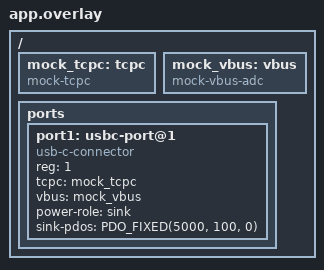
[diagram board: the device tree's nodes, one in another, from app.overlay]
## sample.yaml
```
sample:
  name: USB-C SINK
tests:
  sample.usbc.sink:
    depends_on: tcpc
    tags: usbc
    platform_allow: b_g474e_dpow1
    integration_platforms:
      - b_g474e_dpow1
    harness: console
    harness_config:
      type: one_line
      regex:
        - "Unattached.SNK"
  sample.usbc.sink.chunking:
    depends_on: tcpc
    tags: usbc
    platform_allow: b_g474e_dpow1
    integration_platforms:
      - b_g474e_dpow1
    harness: console
    harness_config:
      type: one_line
      regex:
        - "Unattached.SNK"
    extra_configs:
      - CONFIG_USBC_PRL_CHUNKING=y
```

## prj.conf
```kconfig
CONFIG_ZTEST=y
CONFIG_ZTEST_NEW_API=y

CONFIG_LOG=y
CONFIG_USB_DEVICE_LOG_LEVEL_DBG=y
CONFIG_USB_DRIVER_LOG_LEVEL_DBG=y

CONFIG_ADC=y
CONFIG_USBC_STACK=y
CONFIG_USBC_THREAD_PRIORITY=10
```

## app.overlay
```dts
/*
 * Copyright (c) 2022 The Chromium OS Authors.
 *
 * SPDX-License-Identifier: Apache-2.0
 *
 */

#include <dt-bindings/usb-c/pd.h>

/ {
	mock_tcpc: tcpc {
		compatible = "mock-tcpc";
	};

	mock_vbus: vbus {
		compatible = "mock-vbus-adc";
	};

	ports {
		#address-cells = <1>;
		#size-cells = <0>;

		port1: usbc-port@1 {
			compatible = "usb-c-connector"; 
			reg = <1>;
			tcpc = <&mock_tcpc>;
			vbus = <&mock_vbus>;
			power-role = "sink";
			sink-pdos = <PDO_FIXED(5000, 100, 0)>;
		};
	};
};
```

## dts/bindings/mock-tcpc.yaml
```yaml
# Copyright 2022 The Chromium OS Authors
# SPDX-License-Identifier: Apache-2.0

description: |
    Mock TypeC Port Controller used for testing

compatible: "mock-tcpc"

properties:
    hasvconn:
      type: boolean
      required: false
      description: xxx
```

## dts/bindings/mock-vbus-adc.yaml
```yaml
# Copyright 2022 The Chromium OS Authors
# SPDX-License-Identifier: Apache-2.0

description: |
    Mock VBUS used for testing

compatible: "mock-vbus-adc"

properties:
    hasvconn:
      type: boolean
      required: false
      description: xxx
```

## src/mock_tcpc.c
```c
/*
 * Copyright 2022 The Chromium OS Authors
 *
 * SPDX-License-Identifier: Apache-2.0
 */

#define DT_DRV_COMPAT mock_tcpc

#include <zephyr/logging/log.h>

#include <zephyr/device.h>
#include <zephyr/sys/util.h>
#include <zephyr/kernel.h>
#include <string.h>
#include <stddef.h>

#include "mock_tcpc.h"
#include "mock_tester.h"

enum tcpc_state_t test_state;

/**
 * @brief Get the state of the CC1 and CC2 lines
 *
 * @retval 0 on success
 * @retval -EIO on failure
 */
static int mt_get_cc(const struct device *dev,
		       enum tc_cc_voltage_state *cc1,
		       enum tc_cc_voltage_state *cc2)
{
	*cc1 = tester_get_cc1();
	*cc2 = tester_get_cc2();

	return 0;
}

/**
 * @brief Get the CC enable mask. The mask indicates which CC line
 *        is enabled.
 *
 * @retval CC Enable mask (bit 0: CC1, bit 1: CC2)
 */

/**
 * @brief Enable or Disable VCONN
 *
 * @retval 0 on success
 * @retval -EIO on failure
 * @retval -ENOTSUP if not supported
 */
static int mt_set_vconn(const struct device *dev, bool enable)
{
//	const struct mock_tcpc_config *const config = dev->config;
//	struct mock_tcpc_data *data = dev->data;

	return 0; //ret;
}

/**
 * @brief Sets the value of the CC pull up resistor used when operating as a Source
 *
 * @retval 0 on success
 */
static int mt_select_rp_value(const struct device *dev, enum tc_rp_value rp)
{
//	const struct mock_tcpc_config *const config = dev->config;
//	struct mock_tcpc_data *data = dev->data;

//	data->rp = rp;

	return 0;
}

/**
 * @brief Gets the value of the CC pull up resistor used when operating as a Source
 *
 * @retval 0 on success
 */
static int mt_get_rp_value(const struct device *dev, enum tc_rp_value *rp)
{
//	struct tcpc_data *data = dev->data;

//	*rp = data->rp;

	return 0;
}

/**
 * @brief Set the CC pull up or pull down resistors
 *
 * @retval 0 on success
 * @retval -EIO on failure
 */
static int mt_set_cc(const struct device *dev,
		       enum tc_cc_pull cc_pull)
{
//	const struct mock_tcpc_config *const config = dev->config;
//	struct mock_tcpc_data *data = dev->data;
#if 0
	const struct tcpc_config *const config = dev->config;
	struct tcpc_data *data = dev->data;
	uint32_t cr;

	cr = LL_UCPD_ReadReg(config->ucpd_port, CR);

	/*
	 * Always set ANASUBMODE to match desired Rp. TCPM layer has a valid
	 * range of 0, 1, or 2. This range maps to 1, 2, or 3 in ucpd for
	 * ANASUBMODE.
	 */
	cr &= ~UCPD_CR_ANASUBMODE_Msk;
	cr |= STM32_UCPD_CR_ANASUBMODE_VAL(UCPD_RP_TO_ANASUB(data->rp));

	/* Disconnect both pull from both CC lines for R_open case */
	cr &= ~UCPD_CR_CCENABLE_Msk;
	/* Set ANAMODE if cc_pull is Rd */
	if (cc_pull == TC_CC_RD) {
		cr |= (UCPD_CR_ANAMODE | UCPD_CR_CCENABLE_Msk);
		/* Clear ANAMODE if cc_pull is Rp */
	} else if (cc_pull == TC_CC_RP) {
		cr &= ~(UCPD_CR_ANAMODE);
		cr |= ucpd_get_cc_enable_mask(dev);
	}

	/* Update pull values */
	LL_UCPD_WriteReg(config->ucpd_port, CR, cr);

#ifdef CONFIG_SOC_SERIES_STM32G0X
	update_stm32g0x_cc_line(config->ucpd_port);
#endif
#endif
	return 0;
}

/**
 * @brief Set the polarity of the CC line, which is the active CC line
 *        used for power delivery.
 *
 * @retval 0 on success
 * @retval -EIO on failure
 * @retval -ENOTSUP if polarity is not supported
 */
static int mt_cc_set_polarity(const struct device *dev,
				enum tc_cc_polarity polarity)
{
//	const struct mock_tcpc_config *const config = dev->config;
//	struct mock_tcpc_data *data = dev->data;
#if 0
	const struct tcpc_config *const config = dev->config;
	uint32_t cr;

	cr = LL_UCPD_ReadReg(config->ucpd_port, CR);

	/*
	 * Polarity impacts the PHYCCSEL, CCENABLE, and CCxTCDIS fields. This
	 * function is called when polarity is updated at TCPM layer. STM32Gx
	 * only supports POLARITY_CC1 or POLARITY_CC2 and this is stored in the
	 * PHYCCSEL bit in the CR register.
	 */

	if (polarity == TC_POLARITY_CC1) {
		cr &= ~UCPD_CR_PHYCCSEL;
	} else if (polarity == TC_POLARITY_CC2) {
		cr |= UCPD_CR_PHYCCSEL;
	} else {
		return -ENOTSUP;
	}

	/* Update polarity */
	LL_UCPD_WriteReg(config->ucpd_port, CR, cr);
#endif
	return 0;
}

/**
 * @brief Enable or Disable Power Delivery
 *
 * @retval 0 on success
 * @retval -EIO on failure
 */
static int mt_set_rx_enable(const struct device *dev, bool enable)
{
	struct mock_tcpc_data *data = dev->data;

	data->rx_enable = enable;

	return 0;
}

/**
 * @brief Set the Power and Data role used when sending goodCRC messages
 *
 * @retval 0 on success
 * @retval -EIO on failure
 */
static int mt_set_roles(const struct device *dev,
			  enum tc_power_role power_role,
			  enum tc_data_role data_role)
{
	struct mock_tcpc_data *data = dev->data;

	data->msg_header.pr = power_role;
	data->msg_header.dr = data_role;

	return 0;
}

/**
 * @brief Enable the reception of SOP Prime messages
 *
 * @retval 0 on success
 * @retval -EIO on failure
 */
static int mt_sop_prime_enable(const struct device *dev, bool enable)
{
//	const struct mock_tcpc_config *const config = dev->config;
//	struct mock_tcpc_data *data = dev->data;

	/* Update static variable used to filter SOP//SOP'' messages */
//	data->ucpd_rx_sop_prime_enabled = enable;

	return 0;
}

/**
 * @brief Transmit a power delivery message
 *
 * @retval 0 on success
 * @retval -EFAULT on failure
 */
static int mt_transmit_data(const struct device *dev, struct pd_msg *msg)
{
	struct mock_tcpc_data *data = dev->data;

	switch (test_state) {
	case TS_SEND_GOODCRC:
		memcpy(&data->tx_msg, msg, sizeof(struct pd_msg));
		data->alert_handler(dev, data->alert_data,
					TCPC_ALERT_TRANSMIT_MSG_SUCCESS);
		tester_start_sender_response_timer();
		data->pending_tx_msg = true;
		break;
	case TS_DONT_SEND_GOODCRC:
		break;
	}

	return 0;
}

static bool mt_is_rx_pending_msg(const struct device *dev,
                                   enum pd_packet_type *type)
{
	struct mock_tcpc_data *data = dev->data;

	if (data->pending_rx_msg == false) {
		return false;
	}

	if (type != NULL) {
		*type = data->rx_msg.type;
	}

	return true;
}

/**
 * @brief Retrieves the Power Delivery message from the TCPC
 *	  The UUT calls this function in the Protocol Layer
 *	  to receive the message from the TCPC.
 *
 * @retval number of bytes received
 * @retval -EIO on no message to retrieve
 * @retval -EFAULT on buf being NULL
 */
static int mt_receive_data(const struct device *dev, struct pd_msg *msg)
{
	struct mock_tcpc_data *data = dev->data;

	if (msg == NULL) {
		return -EFAULT;
	}

	/* Make sure we have a message to retrieve */
	if (mt_is_rx_pending_msg(dev, NULL) == false) {
		return -EIO;
	}

	data->pending_rx_msg = false;

	if (data->rx_msg.type == PD_PACKET_TX_HARD_RESET) {
		data->alert_handler(dev, data->alert_data,
			TCPC_ALERT_HARD_RESET_RECEIVED);
		return -EIO;
	}

	memcpy(msg, &data->rx_msg, sizeof(struct pd_msg));

	return msg->len + MSG_HEADER_SIZE;
}

/**
 * @brief Enable or Disable BIST Test mode
 *
 * return 0 on success
 * return -EIO on failure
 */
static int mt_set_bist_test_mode(const struct device *dev,
				   bool enable)
{
//	const struct mock_tcpc_config *const config = dev->config;
//	struct mock_tcpc_data *data = dev->data;

	return 0;
}

/**
 * @brief Dump a set of TCPC registers
 *
 * @retval 0 on success
 * @retval -EIO on failure
 */
static int mt_dump_std_reg(const struct device *dev)
{

	return 0;
}

/**
 * @brief Sets the alert function that's called when an interrupt is triggered
 *        due to a TCPC alert
 *
 * @retval 0 on success
 * @retval -EINVAL on failure
 */
static int mt_set_alert_handler_cb(const struct device *dev,
				     tcpc_alert_handler_cb_t handler, void *alert_data)
{
	struct mock_tcpc_data *data = dev->data;

	data->alert_handler = handler;
	data->alert_data = alert_data;

	return 0;
}

/**
 * @brief Sets a callback that can enable or disable VCONN if the TCPC is
 *        unable to or the system is configured in a way that does not use
 *        the VCONN control capabilities of the TCPC
 *
 */
static void mt_set_vconn_cb(const struct device *dev,
			      tcpc_vconn_control_cb_t vconn_cb)
{
//	const struct mock_tcpc_config *const config = dev->config;
//	struct mock_tcpc_data *data = dev->data;
}

/**
 * @brief Initializes the MOCK TCPC
 *
 * @retval 0 on success
 * @retval -EIO on failure
 */
static int mt_init(const struct device *dev)
{
	struct mock_tcpc_data *data = dev->data;

	test_state = TS_SEND_GOODCRC;

	/* Give tester access to the mock tcpc device */
	tester_set_tcpc_device(data);
	data->pending_rx_msg = false;
	data->pending_tx_msg = false;
	return 0;
}

void tcpc_set_state(enum tcpc_state_t ts)
{
	test_state = ts;	
}


static const struct tcpc_driver_api driver_api = {
	.init =			mt_init,
	.set_alert_handler_cb =	mt_set_alert_handler_cb,
	.get_cc =		mt_get_cc,
	.set_rx_enable =	mt_set_rx_enable,
	.is_rx_pending_msg =	mt_is_rx_pending_msg,
	.receive_data =		mt_receive_data,
	.transmit_data =	mt_transmit_data,
	.select_rp_value =	mt_select_rp_value,
	.get_rp_value =		mt_get_rp_value,
	.set_cc =		mt_set_cc,
	.set_roles =		mt_set_roles,
	.set_vconn_cb =		mt_set_vconn_cb,
	.set_vconn =		mt_set_vconn,
	.set_cc_polarity =	mt_cc_set_polarity,
	.dump_std_reg =		mt_dump_std_reg,
	.set_bist_test_mode =	mt_set_bist_test_mode,
	.sop_prime_enable =	mt_sop_prime_enable,
};

#define TCPC_DRIVER_INIT(inst)						\
	static struct mock_tcpc_data drv_data_##inst;			\
	static const struct mock_tcpc_config drv_config_##inst;		\
	DEVICE_DT_INST_DEFINE(inst,					\
			      &mt_init,					\
			      NULL,					\
			      &drv_data_##inst,				\
			      &drv_config_##inst,			\
			      POST_KERNEL,				\
			      CONFIG_USBC_INIT_PRIORITY,		\
			      &driver_api);

DT_INST_FOREACH_STATUS_OKAY(TCPC_DRIVER_INIT)
```

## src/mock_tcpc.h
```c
/*
 * Copyright (c) 2022  The Chromium OS Authors
 *
 * SPDX-License-Identifier: Apache-2.0
 */

#ifndef ZEPHYR_MOCK_TCPC_PRIV_H_
#define ZEPHYR_MOCK_TCPC_PRIV_H_

#include <zephyr/sys/util.h>
#include <zephyr/drivers/usb_c/usbc_tcpc.h>

/**
 * @brief The packet type(SOP*) consists of 2-bytes
 */
#define PACKET_TYPE_SIZE 2

/**
 * @brief The message header consists of 2-bytes
 */
#define MSG_HEADER_SIZE 2

/**
 * @brief USB PD message buffer length.
 */
#define UCPD_BUF_LEN (PD_MAX_EXTENDED_MSG_LEN +	\
		      PACKET_TYPE_SIZE +	\
		      MSG_HEADER_SIZE)

/**
 * @brief UCPD alert mask used for enabling alerts
 *        used to receive a message
 */
#define UCPD_IMR_RX_INT_MASK (UCPD_IMR_RXNEIE |	     \
			      UCPD_IMR_RXORDDETIE |  \
			      UCPD_IMR_RXHRSTDETIE | \
			      UCPD_IMR_RXOVRIE |     \
			      UCPD_IMR_RXMSGENDIE)
/**
 * @brief UCPD alert mask used for clearing alerts
 *        used to receive a message
 */
#define UCPD_ICR_RX_INT_MASK (UCPD_ICR_RXORDDETCF |  \
			      UCPD_ICR_RXHRSTDETCF | \
			      UCPD_ICR_RXOVRCF |     \
			      UCPD_ICR_RXMSGENDCF)

/**
 * @brief UCPD alert mask used for enabling alerts
 *        used to transmit a message
 */
#define UCPD_IMR_TX_INT_MASK (UCPD_IMR_TXISIE |	     \
			      UCPD_IMR_TXMSGDISCIE | \
			      UCPD_IMR_TXMSGSENTIE | \
			      UCPD_IMR_TXMSGABTIE |  \
			      UCPD_IMR_TXUNDIE)

/**
 * @brief UCPD alert mask used for clearing alerts
 *        used to transmit a message
 */
#define UCPD_ICR_TX_INT_MASK (UCPD_ICR_TXMSGDISCCF | \
			      UCPD_ICR_TXMSGSENTCF | \
			      UCPD_ICR_TXMSGABTCF |  \
			      UCPD_ICR_TXUNDCF)

/**
 * @brief UCPD alert mask for all alerts
 */
#define UCPD_ICR_ALL_INT_MASK (UCPD_ICR_FRSEVTCF |    \
			       UCPD_ICR_TYPECEVT2CF | \
			       UCPD_ICR_TYPECEVT1CF | \
			       UCPD_ICR_RXMSGENDCF |  \
			       UCPD_ICR_RXOVRCF |     \
			       UCPD_ICR_RXHRSTDETCF | \
			       UCPD_ICR_RXORDDETCF |  \
			       UCPD_ICR_TXUNDCF |     \
			       UCPD_ICR_HRSTSENTCF |  \
			       UCPD_ICR_HRSTDISCCF |  \
			       UCPD_ICR_TXMSGABTCF |  \
			       UCPD_ICR_TXMSGSENTCF | \
			       UCPD_ICR_TXMSGDISCCF)

/**
 * @brief Map UCPD ANASUB value to TCPC RP value
 *
 * @param r UCPD ANASUB value
 */
#define UCPD_ANASUB_TO_RP(r) ((r - 1) & 0x3)

/**
 * @brief Map TCPC RP value to UCPD ANASUB value
 *
 * @param r TCPC RP value
 */
#define UCPD_RP_TO_ANASUB(r) ((r + 1) & 0x3)

/**
 * @brief Create value for writing to UCPD CR ANASUBMOD
 */
#define STM32_UCPD_CR_ANASUBMODE_VAL(x) ((x) << UCPD_CR_ANASUBMODE_Pos)

/**
 * @brief UCPD VSTATE CCx open value when in source mode
 */
#define STM32_UCPD_SR_VSTATE_OPEN 3

/**
 * @brief UCPD VSTATE CCx RA value when in source mode
 */
#define STM32_UCPD_SR_VSTATE_RA 0

/**
 * @brief PD message send retry count for Rev 2.0
 */
#define UCPD_N_RETRY_COUNT_REV20 3

/**
 * @brief PD message send retry count for Rev 3.0
 */
#define UCPD_N_RETRY_COUNT_REV30 2

enum tcpc_state_t {
	TS_SEND_GOODCRC,
	TS_DONT_SEND_GOODCRC,
};

void tcpc_set_state(enum tcpc_state_t ts);

/**
 * @brief Events for ucpd_alert_handler
 */
enum {
	/* Request to send a goodCRC message */
	UCPD_EVT_GOOD_CRC_REQ,
	/* Request to send a power delivery message */
	UCPD_EVT_TCPM_MSG_REQ,
	/* Request to send a Hard Reset message */
	UCPD_EVT_HR_REQ,
	/* Transmission of power delivery message failed */
	UCPD_EVT_TX_MSG_FAIL,
	/* Transmission of power delivery message was discarded */
	UCPD_EVT_TX_MSG_DISC,
	/* Transmission of power delivery message was successful */
	UCPD_EVT_TX_MSG_SUCCESS,
	/* Transmission of Hard Reset message was successful */
	UCPD_EVT_HR_DONE,
	/* Transmission of Hard Reset message failed */
	UCPD_EVT_HR_FAIL,
	/* A goodCRC message was received */
	UCPD_EVT_RX_GOOD_CRC,
	/* A power delivery message was received */
	UCPD_EVT_RX_MSG,
	/* A CC event occurred */
	UCPD_EVT_EVENT_CC,
	/* A Hard Reset message was received */
	UCPD_EVT_HARD_RESET_RECEIVED,
};

/**
 * @brief GoodCRC message header roles
 */
struct msg_header_info {
	/* Power Role */
	enum tc_power_role pr;
	/* Data Role */
	enum tc_data_role dr;
};

/**
 * @brief Buffer for holding the received message
 */
union pd_buffer {
	/* Power Delivery message header */
	uint16_t header;
	/* Power Deliver message data including the message header */
	uint8_t msg[UCPD_BUF_LEN];
};

/**
 * @brief Struct used for transmitting a power delivery message
 */
struct ucpd_tx_desc {
	/* Type of the message */
	enum pd_packet_type type;
	/* Length of the message */
	int msg_len;
	/* Index of the current byte to transmit */
	int msg_index;
	/* Power Delivery message to transmit */
	union pd_buffer data;
};

/**
 * @brief Driver config
 */
struct mock_tcpc_config {
	int k;
};

/**
 * @brief Driver data
 */
struct mock_tcpc_data {
	bool rx_enable;
	bool pending_rx_msg;
	struct pd_msg rx_msg;
	bool pending_tx_msg;
	struct pd_msg tx_msg;

	void *alert_data;
        /* Application's alert handler callback */
        tcpc_alert_handler_cb_t alert_handler;



	/* VCONN callback function */
	tcpc_vconn_control_cb_t vconn_cb;

	/* CC Rp value */
	enum tc_rp_value rp;

	/* PD Rx variables */

	/* Number of RX bytes received */
	int ucpd_rx_byte_count;
	/* Buffer to hold the received bytes */
	uint8_t ucpd_rx_buffer[UCPD_BUF_LEN];
	/* GoodCRC message ID */
	int ucpd_crc_id;
	/* Flag to receive or ignore SOP Prime messages */
	bool ucpd_rx_sop_prime_enabled;
	/* Flag set to true when receiving a message */
	bool ucpd_rx_msg_active;
	/* Flag set to true when in RX BIST Mode */
	bool ucpd_rx_bist_mode;

	/* Tx message variables */

	/* Request to send a transmission message */
	int ucpd_tx_request;
	/* Transmission message ID */
	int msg_id_match;
	/* Retry count on failure to transmit a message */
	int tx_retry_count;
	/* Max number of reties before giving up */
	int tx_retry_max;

	/* GoodCRC message Header */
	struct msg_header_info msg_header;
	/* Track VCONN on/off state */
	bool ucpd_vconn_enable;
};

#endif /* ZEPHYR_MOCK_TCPC_PRIV_H_ */
```

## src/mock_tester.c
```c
#include <zephyr/kernel.h>
#include <string.h>
#include <stddef.h>
#include <zephyr/drivers/usb_c/usbc_pd.h>

#include "mock_tester.h"
#include "mock_tcpc.h"

struct mock_tester_t {
	struct mock_tcpc_data *tcpc;
	enum tc_cc_voltage_state cc1;
	enum tc_cc_voltage_state cc2;
	int vbus;
	struct pd_msg tx_msg;
	struct pd_msg rx_msg;

	int msg_id;
	enum pd_rev_type rev;
	enum tc_power_role power_role;
	enum tc_data_role data_role;
};

static struct mock_tester_t tester;

void tester_msgid_set(int id)
{
	tester.tx_msg.header.message_id = id & 7;
}

void tester_msgid_inc(void)
{
	tester.tx_msg.header.message_id++;
	tester.tx_msg.header.message_id &= 7;
}

int tester_get_msgid(void)
{
	return tester.tx_msg.header.message_id;
}

void tester_transmit_data(struct pd_msg *msg)
{
	if (tester.tcpc->rx_enable) {
		memcpy(&tester.tcpc->rx_msg, msg, sizeof(struct pd_msg));
		tester.tcpc->pending_rx_msg = true;
	}
}

void tester_send_hard_reset(void)
{
	memset(&tester.tcpc->rx_msg, 0, sizeof(struct pd_msg));
	tester.tcpc->rx_msg.type = PD_PACKET_TX_HARD_RESET;
	tester.tcpc->pending_rx_msg = true;
}

void tester_send_ctrl_msg(enum pd_ctrl_msg_type type, bool inc_msgid)
{
	tester.tx_msg.type = PD_PACKET_SOP;
	tester.tx_msg.header.message_type = type;
	tester.tx_msg.header.port_data_role = tester.data_role;
	tester.tx_msg.header.specification_revision = tester.rev;
	tester.tx_msg.header.port_power_role = tester.power_role;
	if (inc_msgid) {
		tester_msgid_inc();
	}
	tester.tx_msg.header.number_of_data_objects = 0;
	tester.tx_msg.header.extended = 0;
	tester.tx_msg.len = 0;

	tester_transmit_data(&tester.tx_msg);
}

void tester_send_data_msg(enum pd_data_msg_type type, uint32_t *data, uint32_t len, bool inc_msgid)
{
	tester.tx_msg.type = PD_PACKET_SOP;
	tester.tx_msg.header.message_type = type;
	tester.tx_msg.header.port_data_role = tester.data_role;
	tester.tx_msg.header.specification_revision = tester.rev;
	tester.tx_msg.header.port_power_role = tester.power_role;
	if (inc_msgid) {
		tester_msgid_inc();
	}
	tester.tx_msg.header.number_of_data_objects = len;
	tester.tx_msg.header.extended = 0;
	tester.tx_msg.len = len * 4;
	memcpy(tester.tx_msg.data, (uint8_t *)data, len * 4);

	tester_transmit_data(&tester.tx_msg);
}

enum pd_rev_type tester_get_rev(void)
{
	return tester.rev;
}

void tester_set_rev_pd2(void)
{
	tester.rev = PD_REV20;
}

void tester_set_rev_pd3(void)
{
        tester.rev = PD_REV30;
}

void tester_set_power_role_source(void)
{
	tester.power_role = TC_ROLE_SOURCE;
}

void tester_set_data_role_ufp(void)
{
	tester.data_role = TC_ROLE_UFP;
}

void tester_set_data_role_dfp(void)
{
	tester.data_role = TC_ROLE_DFP;
}

void tester_set_tcpc_device(struct mock_tcpc_data *tcpc)
{
	tester.tcpc = tcpc;
}

void tester_disconnected(void)
{
	tester_apply_vbus(0);
	tester_apply_cc(TC_CC_VOLT_OPEN, TC_CC_VOLT_OPEN);
	tester_msgid_set(0);
}

void tester_apply_cc(enum tc_cc_voltage_state cc1,
		     enum tc_cc_voltage_state cc2)
{
        tester.cc1 = cc1;
        tester.cc2 = cc2;
}

void tester_apply_rp(enum tc_rp_value cc1, enum tc_rp_value cc2)
{
	switch (cc1) {
	case TC_RP_USB:
		tester.cc1 = TC_CC_VOLT_RP_DEF;
		break;
	case TC_RP_1A5:
		tester.cc1 = TC_CC_VOLT_RP_1A5;
		break;
	case TC_RP_3A0:
		tester.cc1 = TC_CC_VOLT_RP_3A0;
		break;
	case TC_RP_RESERVED:
		tester.cc1 = TC_CC_VOLT_OPEN;
		break;
	}

	switch (cc2) {
	case TC_RP_USB:
		tester.cc2 = TC_CC_VOLT_RP_DEF;
		break;
	case TC_RP_1A5:
		tester.cc2 = TC_CC_VOLT_RP_1A5;
		break;
	case TC_RP_3A0:
		tester.cc2 = TC_CC_VOLT_RP_3A0;
		break;
	case TC_RP_RESERVED:
		tester.cc2 = TC_CC_VOLT_OPEN;
		break;
	}
}

enum tc_cc_voltage_state tester_get_cc1(void)
{
	return tester.cc1;
}

enum tc_cc_voltage_state tester_get_cc2(void)
{
	return tester.cc2;
}

void tester_apply_vbus_level(enum tc_vbus_level level)
{
	switch (level) {
	case TC_VBUS_SAFE0V:
		tester.vbus = PD_V_SAFE_0V_MAX_MV - 1;
		break;
	case TC_VBUS_PRESENT:
		tester.vbus = PD_V_SAFE_5V_MIN_MV;
		break;
	case TC_VBUS_REMOVED:
		tester.vbus = TC_V_SINK_DISCONNECT_MIN_MV - 1;
		break;
	}
}

void tester_apply_vbus(int mv)
{
	tester.vbus = mv;
}

int tester_get_vbus(void)
{
	return tester.vbus;
}

void tester_get_uut_tx_data(struct pd_msg *msg)
{
	int loop = 0;

	do {
		loop++;
		k_msleep(1);
	} while ((loop < 500) && tester.tcpc->pending_tx_msg == false);

	tester.tcpc->pending_tx_msg = false;
	memcpy(msg, &tester.tcpc->tx_msg, sizeof(struct pd_msg));
}

bool tester_is_rx_msg_pending(void)
{
	return tester.tcpc->pending_rx_msg;
}
```

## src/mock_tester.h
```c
/*
 * Copyright (c) 2022  The Chromium OS Authors
 *
 * SPDX-License-Identifier: Apache-2.0
 */

#ifndef ZEPHYR_MOCK_TESTER_H_
#define ZEPHYR_MOCK_TESTER_H_

#include <zephyr/device.h>
#include <zephyr/sys/util.h>
#include <zephyr/drivers/usb_c/usbc_tc.h>

#include "mock_tcpc.h"

void tester_disconnected(void);
void tester_apply_cc(enum tc_cc_voltage_state cc1,
		enum tc_cc_voltage_state cc2);
void tester_apply_rp(enum tc_rp_value cc1, enum tc_rp_value cc2);
enum tc_cc_voltage_state tester_get_cc1(void);
enum tc_cc_voltage_state tester_get_cc2(void);
void tester_apply_vbus_level(enum tc_vbus_level level);
void tester_apply_vbus(int mv);
int tester_get_vbus(void);
void tester_send_msg_to_uut(struct pd_msg *msg);
void tester_get_msg_from_uut(struct pd_msg *msg);
void tester_set_tcpc_device(struct mock_tcpc_data *tcpc);
void tester_send_ctrl_msg(enum pd_ctrl_msg_type type, bool inc_msgid);
void tester_send_data_msg(enum pd_data_msg_type type, uint32_t *data, uint32_t len, bool inc_msgid);
void tester_set_rev_pd2(void);
void tester_set_rev_pd3(void);
enum pd_rev_type tester_get_rev(void);
void tester_set_power_role_source(void);
void tester_set_data_role_ufp(void);
void tester_set_data_role_dfp(void);
void tester_msgid_inc(void);
void tester_get_uut_tx_data(struct pd_msg *msg);
int tester_get_msgid(void);
bool tester_is_rx_msg_pending(void);
void tester_send_hard_reset(void);

void tester_start_sender_response_timer(void);

void start_policy_timer(void);
#endif /* ZEPHYR_MOCK_TESTER_H_ */
```

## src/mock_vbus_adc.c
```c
/*
 * Copyright 2022 The Chromium OS Authors
 *
 * SPDX-License-Identifier: Apache-2.0
 */

#define DT_DRV_COMPAT mock_vbus_adc

#include <zephyr/logging/log.h>
LOG_MODULE_REGISTER(usbc_vbus_adc, CONFIG_USBC_LOG_LEVEL);

#include <zephyr/device.h>
#include <zephyr/sys/util.h>
#include <zephyr/kernel.h>
#include <zephyr/drivers/usb_c/usbc_pd.h>
#include <zephyr/drivers/usb_c/usbc_vbus.h>
#include <stddef.h>

#include "mock_vbus_adc.h"
#include "mock_tester.h"

/**
 * @brief Measure VBUS
 *
 * @retval 0 on success
 */
static int mt_adc_vbus_measure(const struct device *dev, int *meas)
{
	__ASSERT(meas != NULL, "ADC VBUS meas must not be NULL");

	*meas = tester_get_vbus();

	return 0;
}

/**
 * @brief Checks if VBUS is at a particular level
 *
 * @retval true if VBUS is at the level voltage, else false
 */
static bool mt_adc_vbus_check_level(const struct device *dev,
				 enum tc_vbus_level level)
{
	int meas;

	meas = tester_get_vbus();

	switch (level) {
	case TC_VBUS_SAFE0V:
		return (meas < PD_V_SAFE_0V_MAX_MV);
	case TC_VBUS_PRESENT:
		return (meas >= PD_V_SAFE_5V_MIN_MV);
	case TC_VBUS_REMOVED:
		return (meas < TC_V_SINK_DISCONNECT_MAX_MV);
	}

	return false;
}

/**
 * @brief Sets pin to discharge VBUS
 *
 * @retval 0 on success
 */
static int mt_adc_vbus_discharge(const struct device *dev,
			      bool enable)
{
	return 0;
}

/**
 * @brief Sets pin to enable VBUS measurments
 *
 * @retval 0 on success
 */
static int mt_adc_vbus_enable(const struct device *dev,
			   bool enable)
{
	return 0;
}

/**
 * @brief Initializes the ADC VBUS Driver
 *
 * @retval 0 on success
 */
static int mt_adc_vbus_init(const struct device *dev)
{
	return 0;
}

static const struct usbc_vbus_driver_api driver_api = {
	.measure = mt_adc_vbus_measure,
	.check_level = mt_adc_vbus_check_level,
	.discharge = mt_adc_vbus_discharge,
	.enable = mt_adc_vbus_enable
};

BUILD_ASSERT(DT_NUM_INST_STATUS_OKAY(DT_DRV_COMPAT) > 0,
	     "No compatible USB-C VBUS Measurement instance found");

#define DRIVER_INIT(inst)								\
	DEVICE_DT_INST_DEFINE(inst,							\
			      &mt_adc_vbus_init,					\
			      NULL,							\
			      NULL, \
			      NULL, \
			      POST_KERNEL,						\
			      CONFIG_USBC_INIT_PRIORITY,				\
			      &driver_api);

#if 0
#define DRIVER_INIT(inst)                                                               \
        static struct mock_vbus_data drv_data_##inst;                                   \
        static const struct mock_vbus_config drv_config_##inst;                         \
        DEVICE_DT_INST_DEFINE(inst,                                                     \
                              &mt_adc_vbus_init,                                        \
                              NULL,                                                     \
                              &drv_data_##inst,                                         \
                              &drv_config_##inst,                                       \
                              POST_KERNEL,                                              \
                              CONFIG_USBC_INIT_PRIORITY,                                \
                              &driver_api);

#endif


DT_INST_FOREACH_STATUS_OKAY(DRIVER_INIT)
```

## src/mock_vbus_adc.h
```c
/*
 * Copyright (c) 2022  The Chromium OS Authors
 *
 * SPDX-License-Identifier: Apache-2.0
 */

#ifndef ZEPHYR_MOCK_VBUS_ADC_PRIV_H_
#define ZEPHYR_MOCK_VBUS_ADC_PRIV_H_

/**
 * @brief Driver config
 */
struct mock_vbus_config {
	int test;
};

/**
 * @brief Driver data
 */
struct mock_vbus_data {
	int test;
};

#endif /* ZEPHYR_MOCK_VBUS_ADC_PRIV_H_ */
```
